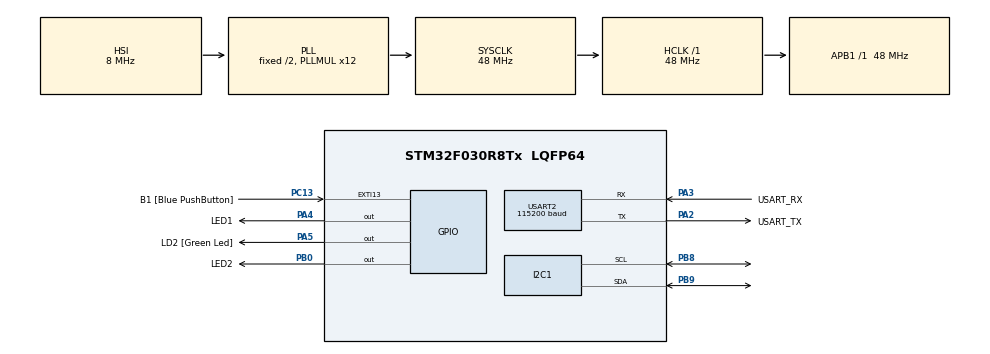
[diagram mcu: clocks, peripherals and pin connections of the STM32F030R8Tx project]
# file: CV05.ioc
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Dma.Request0=USART2_RX
Dma.USART2_RX.0.Direction=DMA_PERIPH_TO_MEMORY
Dma.USART2_RX.0.Instance=DMA1_Channel5
Dma.USART2_RX.0.MemDataAlignment=DMA_MDATAALIGN_BYTE
Dma.USART2_RX.0.MemInc=DMA_MINC_ENABLE
Dma.USART2_RX.0.Mode=DMA_CIRCULAR
Dma.USART2_RX.0.PeriphDataAlignment=DMA_PDATAALIGN_BYTE
Dma.USART2_RX.0.PeriphInc=DMA_PINC_DISABLE
Dma.USART2_RX.0.Priority=DMA_PRIORITY_LOW
I2C1.Timing=0x00201D2B
Mcu.Family=STM32F0
Mcu.Name=STM32F030R8Tx
Mcu.Package=LQFP64
NVIC.DMA1_Channel4_5_IRQn=true\:0\:0\:false\:false\:true\:false\:true\:true
PA13.GPIO_Label=TMS
PA13.Mode=Serial_Wire
PA13.Signal=SYS_SWDIO
PA14.GPIO_Label=TCK
PA14.Mode=Serial_Wire
PA14.Signal=SYS_SWCLK
PA2.GPIO_Label=USART_TX
PA2.GPIO_Mode=GPIO_MODE_AF_PP
PA2.GPIO_PuPd=GPIO_NOPULL
PA2.GPIO_Speed=GPIO_SPEED_FREQ_LOW
PA2.Mode=Asynchronous
PA2.Signal=USART2_TX
PA3.GPIO_Label=USART_RX
PA3.GPIO_Mode=GPIO_MODE_AF_PP
PA3.GPIO_PuPd=GPIO_NOPULL
PA3.GPIO_Speed=GPIO_SPEED_FREQ_LOW
PA3.Mode=Asynchronous
PA3.Signal=USART2_RX
PA4.GPIO_Label=LED1
PA4.Signal=GPIO_Output
PA5.GPIO_Label=LD2 [Green Led]
PA5.GPIO_Mode=GPIO_MODE_OUTPUT_PP
PA5.GPIO_PuPd=GPIO_NOPULL
PA5.GPIO_Speed=GPIO_SPEED_FREQ_LOW
PA5.Signal=GPIO_Output
PB0.GPIO_Label=LED2
PB0.Signal=GPIO_Output
PB8.Mode=I2C
PB8.Signal=I2C1_SCL
PB9.Mode=I2C
PB9.Signal=I2C1_SDA
PC13.GPIO_Label=B1 [Blue PushButton]
PC13.GPIO_ModeDefaultEXTI=GPIO_MODE_IT_FALLING
PC13.Signal=GPXTI13
PC14-OSC32_IN.Mode=LSE-External-Oscillator
PC14-OSC32_IN.Signal=RCC_OSC32_IN
PC15-OSC32_OUT.Mode=LSE-External-Oscillator
PC15-OSC32_OUT.Signal=RCC_OSC32_OUT
PF0-OSC_IN.Mode=HSE-External-Clock-Source
PF0-OSC_IN.Signal=RCC_OSC_IN
PF1-OSC_OUT.Signal=RCC_OSC_OUT
ProjectManager.HeapSize=0x200
ProjectManager.StackSize=0x400
ProjectManager.TargetToolchain=STM32CubeIDE
RCC.AHBFreq_Value=48000000
RCC.APB1Freq_Value=48000000
RCC.APB1TimFreq_Value=48000000
RCC.HCLKFreq_Value=48000000
RCC.PLLMUL=RCC_PLL_MUL12
RCC.SYSCLKFreq_VALUE=48000000
RCC.SYSCLKSource=RCC_SYSCLKSOURCE_PLLCLK
USART2.BaudRate=115200
USART2.VirtualMode-Asynchronous=VM_ASYNC
board=NUCLEO-F030R8

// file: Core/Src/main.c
/* USER CODE BEGIN Header */
/**
  ******************************************************************************
  * @file           : main.c
  * @brief          : Main program body
  ******************************************************************************
  * @attention
  *
  * Copyright (c) 2024 STMicroelectronics.
  * All rights reserved.
  *
  * This software is licensed under terms that can be found in the LICENSE file
  * in the root directory of this software component.
  * If no LICENSE file comes with this software, it is provided AS-IS.
  *
  ******************************************************************************
  */
/* USER CODE END Header */
#include "main.h"
#include "dma.h"
#include "i2c.h"
#include "usart.h"
#include "gpio.h"

/* USER CODE BEGIN Includes */
#include "uart_processing.h"
/* USER CODE END Includes */

/* USER CODE BEGIN PV */
#define RX_BUFFER_LEN 64
static uint8_t uart_rx_buf[RX_BUFFER_LEN];
static volatile uint16_t uart_rx_read_ptr = 0;
#define uart_rx_write_ptr (RX_BUFFER_LEN - hdma_usart2_rx.Instance->CNDTR)
/* USER CODE END PV */

void SystemClock_Config(void);

int main(void)
{

  /* MCU Configuration--------------------------------------------------------*/

  /* Reset of all peripherals, Initializes the Flash interface and the Systick. */
  HAL_Init();

  /* Configure the system clock */
  SystemClock_Config();

  /* Initialize all configured peripherals */
  MX_GPIO_Init();
  MX_DMA_Init();
  MX_USART2_UART_Init();
  MX_I2C1_Init();
  /* USER CODE BEGIN 2 */
  HAL_UART_Receive_DMA(&huart2, uart_rx_buf, RX_BUFFER_LEN);

  /* USER CODE END 2 */

  /* Infinite loop */
  /* USER CODE BEGIN WHILE */
  while (1)
  {
		while (uart_rx_read_ptr != uart_rx_write_ptr)
		{
			uint8_t b = uart_rx_buf[uart_rx_read_ptr];
			// increase read pointer
			if (++uart_rx_read_ptr >= RX_BUFFER_LEN)
			{
				uart_rx_read_ptr = 0;
			}
			// process every received byte with the RX state machine
			uart_byte_available(b);
		}

    /* USER CODE END WHILE */

  }
}

void SystemClock_Config(void)
{
  RCC_OscInitTypeDef RCC_OscInitStruct = {0};
  RCC_ClkInitTypeDef RCC_ClkInitStruct = {0};
  RCC_PeriphCLKInitTypeDef PeriphClkInit = {0};

  /** Initializes the RCC Oscillators according to the specified parameters
  * in the RCC_OscInitTypeDef structure.
  */
  RCC_OscInitStruct.OscillatorType = RCC_OSCILLATORTYPE_HSI;
  RCC_OscInitStruct.HSIState = RCC_HSI_ON;
  RCC_OscInitStruct.HSICalibrationValue = RCC_HSICALIBRATION_DEFAULT;
  RCC_OscInitStruct.PLL.PLLState = RCC_PLL_ON;
  RCC_OscInitStruct.PLL.PLLSource = RCC_PLLSOURCE_HSI;
  RCC_OscInitStruct.PLL.PLLMUL = RCC_PLL_MUL12;
  RCC_OscInitStruct.PLL.PREDIV = RCC_PREDIV_DIV1;
  if (HAL_RCC_OscConfig(&RCC_OscInitStruct) != HAL_OK)
  {
    Error_Handler();
  }

  /** Initializes the CPU, AHB and APB buses clocks
  */
  RCC_ClkInitStruct.ClockType = RCC_CLOCKTYPE_HCLK|RCC_CLOCKTYPE_SYSCLK
                              |RCC_CLOCKTYPE_PCLK1;
  RCC_ClkInitStruct.SYSCLKSource = RCC_SYSCLKSOURCE_PLLCLK;
  RCC_ClkInitStruct.AHBCLKDivider = RCC_SYSCLK_DIV1;
  RCC_ClkInitStruct.APB1CLKDivider = RCC_HCLK_DIV1;

  if (HAL_RCC_ClockConfig(&RCC_ClkInitStruct, FLASH_LATENCY_1) != HAL_OK)
  {
    Error_Handler();
  }
  PeriphClkInit.PeriphClockSelection = RCC_PERIPHCLK_I2C1;
  PeriphClkInit.I2c1ClockSelection = RCC_I2C1CLKSOURCE_HSI;
  if (HAL_RCCEx_PeriphCLKConfig(&PeriphClkInit) != HAL_OK)
  {
    Error_Handler();
  }
}

void Error_Handler(void)
{
  __disable_irq();
  while (1)
  {
  }
}
